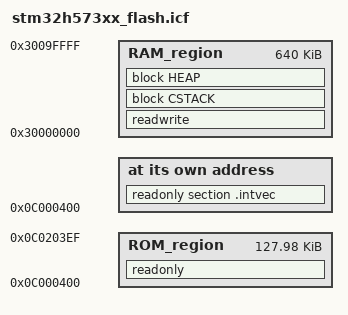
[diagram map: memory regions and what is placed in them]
/*###ICF### Section handled by ICF editor, don't touch! ****/
/*-Editor annotation file-*/
/* IcfEditorFile="$TOOLKIT_DIR$\config\ide\IcfEditor\cortex_v1_0.xml" */
/*-Specials-*/
define symbol S_CODE_OFFSET = 0x00000000; /* Firmware execution area offset from STiROT_Config.xml */
define symbol S_CODE_SIZE = 0x00020000; /* Firmware area size from STiROT_Config.xml */
define exported symbol IMAGE_HEADER_SIZE = 0x400; /* mcuboot headre size */

define exported symbol __ICFEDIT_intvec_start__ = 0x0C000000 + S_CODE_OFFSET + IMAGE_HEADER_SIZE;
/*-Memory Regions-*/
define exported symbol __ICFEDIT_region_ROM_start__     = 0x0C000000 + S_CODE_OFFSET + IMAGE_HEADER_SIZE;
define symbol __ICFEDIT_region_ROM_end__       = 0x0C000000 + S_CODE_OFFSET + S_CODE_SIZE + IMAGE_HEADER_SIZE - 16 - 1;
define exported symbol __ICFEDIT_region_RAM_start__     = 0x30000000;
define exported symbol __ICFEDIT_region_RAM_end__       = 0x3009FFFF;

/*-Sizes-*/
define symbol __ICFEDIT_size_cstack__ = 0x400;
define symbol __ICFEDIT_size_heap__   = 0x200;
/**** End of ICF editor section. ###ICF###*/


define memory mem with size = 4G;
define region ROM_region      = mem:[from __ICFEDIT_region_ROM_start__     to __ICFEDIT_region_ROM_end__];
define region RAM_region      = mem:[from __ICFEDIT_region_RAM_start__     to __ICFEDIT_region_RAM_end__];

define block CSTACK    with alignment = 8, size = __ICFEDIT_size_cstack__   { };
define block HEAP      with alignment = 8, size = __ICFEDIT_size_heap__     { };

initialize by copy { readwrite };
do not initialize  { section .noinit };

place at address mem:__ICFEDIT_intvec_start__ { readonly section .intvec };

place in ROM_region     { readonly };
place in RAM_region     { readwrite,
                          block CSTACK, block HEAP };
